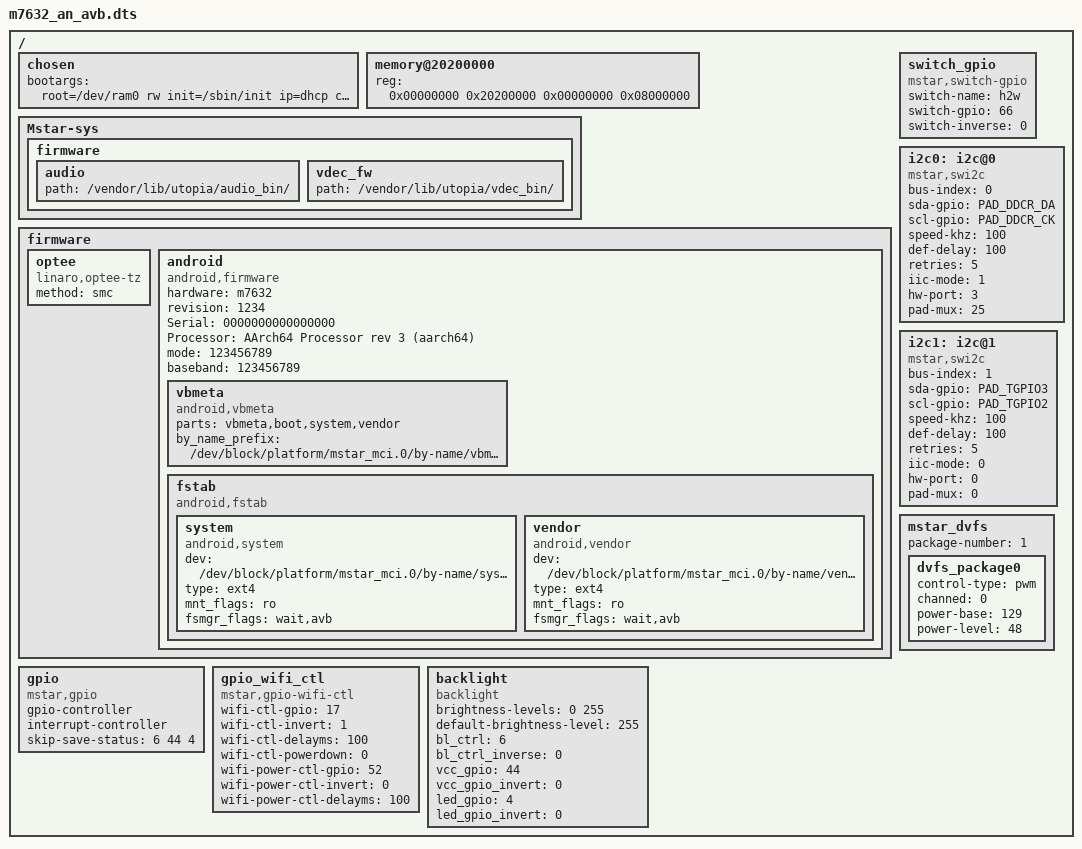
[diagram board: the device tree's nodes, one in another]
/dts-v1/;
#include "../../../../drivers/mstar2/hal/m7632/gpio/mhal_gpio_reg.h"
#include "m7632.dtsi"

/ {
	chosen {
         bootargs = "root=/dev/ram0 rw init=/sbin/init ip=dhcp console=ttyS0,38400,LX_MEM=0x03000000";
        };

	memory@20200000 {
		device_type = "memory";
		reg = <0x00000000 0x20200000 0x00000000 0x08000000>;
	};

	Mstar-sys {
		firmware {
			audio {
				path = "/vendor/lib/utopia/audio_bin/";
			};
			vdec_fw {
				path = "/vendor/lib/utopia/vdec_bin/";
			};
		};
	};

	firmware: firmware {
		optee {
			compatible = "linaro,optee-tz";
			method = "smc";
		};

		android {
			compatible = "android,firmware";
			hardware = "m7632";
			revision = "1234";
			Serial = "0000000000000000";
			Processor = "AArch64 Processor rev 3 (aarch64)";
			mode = "123456789";
			baseband = "123456789";

			vbmeta {
				compatible = "android,vbmeta";
				parts = "vbmeta,boot,system,vendor";
				by_name_prefix ="/dev/block/platform/mstar_mci.0/by-name/vbmeta";
            };

			fstab {
				compatible = "android,fstab";
				system {
					compatible = "android,system";
					dev = "/dev/block/platform/mstar_mci.0/by-name/system";
					type = "ext4";
					mnt_flags = "ro";
					fsmgr_flags = "wait,avb";
				};
				vendor {
					compatible = "android,vendor";
					dev = "/dev/block/platform/mstar_mci.0/by-name/vendor";
					type = "ext4";
					mnt_flags = "ro";
					fsmgr_flags = "wait,avb";
				};
			};
		};
	};

	gpio: gpio {
		compatible = "mstar,gpio";
		gpio-controller;
		#gpio-cells = <1>;
		interrupt-controller;
		skip-save-status = <6 44 4>;
		#interrupt-cells = <2>; /* cell name GPIO_PAD, trigger-type*/
	};

	switch_gpio {
		compatible = "mstar,switch-gpio";
		switch-name = "h2w";
		switch-gpio = <66>;
		switch-inverse = <0>;
	};

	gpio_wifi_ctl {
		compatible = "mstar,gpio-wifi-ctl";
		wifi-ctl-gpio = <17>;
		wifi-ctl-invert = <1>;
		wifi-ctl-delayms = <100>;
		wifi-ctl-powerdown = <0>;
		wifi-power-ctl-gpio = <52>;
		wifi-power-ctl-invert = <0>;
		wifi-power-ctl-delayms = <100>;
	};

	backlight {
		compatible = "backlight";
		brightness-levels = <0 255>;
		default-brightness-level = <255>;
		bl_ctrl = <6>;
		bl_ctrl_inverse = <0>;
		vcc_gpio = <44>;
		vcc_gpio_invert = <0>;
		led_gpio = <4>;
		led_gpio_invert = <0>;
		/* led-pwm-control-support; */
		/* led-pwm-control-channel = <0>; */
		/* led-pwm-control-resume-period = <0xb71a>; */
		/* led-pwm-control-resume-duty = <0xb71a>; */
		/* led-pwm-control-resume-div = <0xff>; */
		/* led-pwm-control-resume-polarity = <0>; */
		/* led-pwm-control-suspend-period = <0xb71a>; */
		/* led-pwm-control-suspend-duty = <0xb71a>; */
		/* led-pwm-control-suspend-div = <0xff>; */
		/* led-pwm-control-suspend-polarity = <0>; */
	};

	i2c0: i2c@0 {
		compatible = "mstar,swi2c";
		bus-index = <0>;
		sda-gpio = <PAD_DDCR_DA>;
		scl-gpio = <PAD_DDCR_CK>;
		speed-khz = <100>;
		def-delay = <100>;
		retries = <5>;
		status = "okay";
		iic-mode = <1>;
		hw-port = <3>;
		pad-mux = <25>;
	};

	i2c1: i2c@1 {
		compatible = "mstar,swi2c";
		bus-index = <1>;
		sda-gpio = <PAD_TGPIO3>;
		scl-gpio = <PAD_TGPIO2>;
		speed-khz = <100>;
		def-delay = <100>;
		retries = <5>;
		status = "okay";
		iic-mode = <0>;
		hw-port = <0>;
		pad-mux = <0>;
	};

    mstar_dvfs: mstar_dvfs {
        package-number = <1>;
        dvfs_package0: dvfs_package0 {
            control-type = "pwm";
            channed = <0>;
            power-base = <129>;
            power-level = <48>;
        };
    };
};
